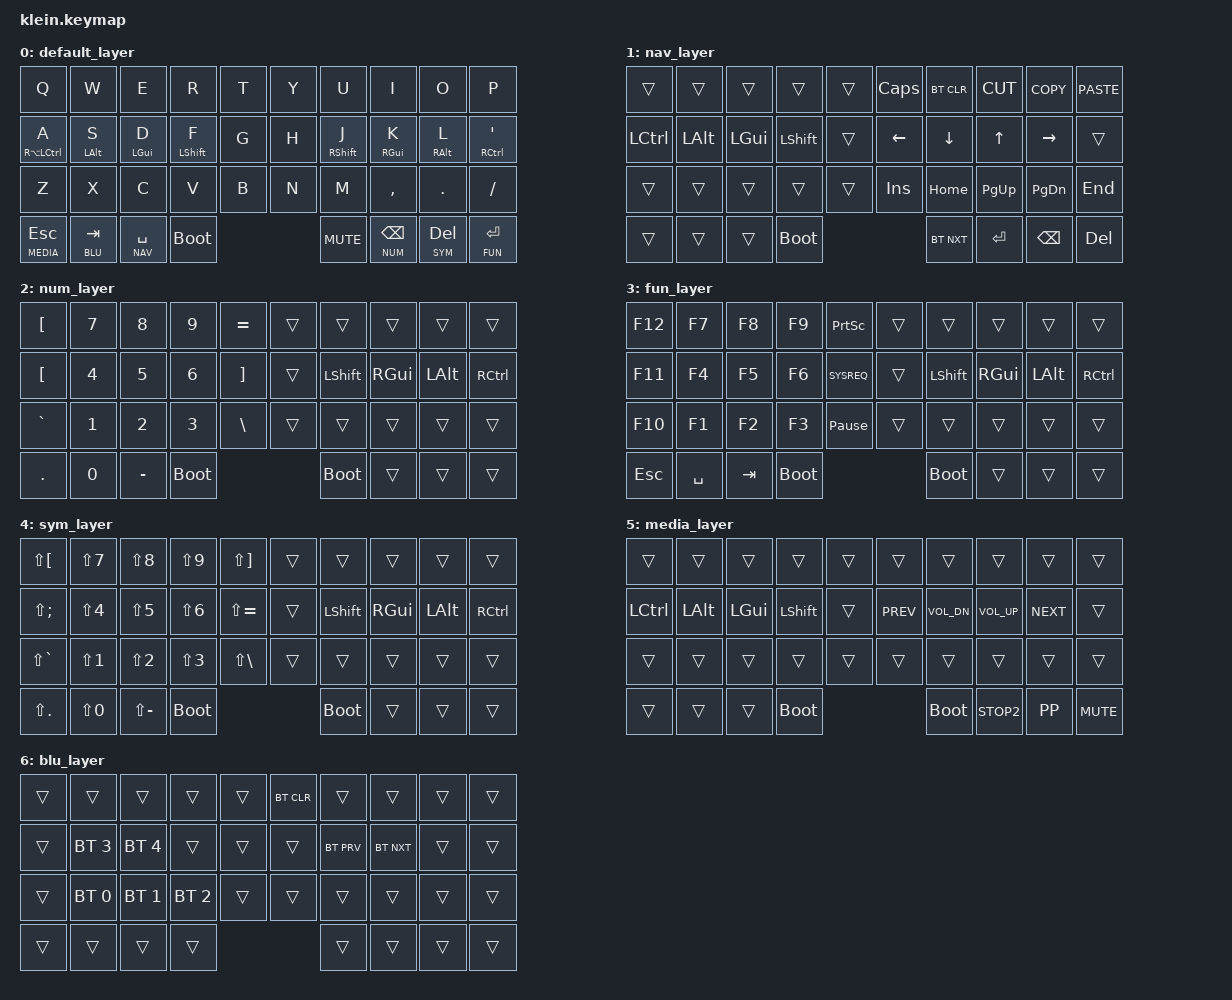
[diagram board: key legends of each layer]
/*
 * Copyright (c) 2020 The ZMK Contributors
 *
 * SPDX-License-Identifier: MIT
 */

#include <behaviors.dtsi>
#include <dt-bindings/zmk/bt.h>
#include <dt-bindings/zmk/keys.h>

#define BASE 0
#define NAV  1
#define NUM  2
#define FUN  3
#define SYM  4
#define MEDIA  5
#define BLU 6

&mt {
    quick-tap-ms = <100>;
    global-quick-tap;
    flavor = "tap-preferred";
    tapping-term-ms = <180>;
};

/ {
    combos {
        compatible = "zmk,combos";

        copy {
            bindings = <&kp LG(C)>;
            key-positions = <21 22>;
            layers = <0>;
        };

        paste {
            bindings = <&kp LG(V)>;
            key-positions = <22 23>;
            layers = <0>;
        };

        leftParet {
            bindings = <&kp LEFT_PARENTHESIS>;
            key-positions = <6 7>;
        };

        rightParet {
            bindings = <&kp RIGHT_PARENTHESIS>;
            key-positions = <7 8>;
            layers = <0>;
        };
    };

    keymap {
        compatible = "zmk,keymap";

        default_layer {
            //          ------------------------------------------------------------------------------------------------------------
            //          |  Q  |  W  |  E   |  R   |  T   |                                           |  Y   |  U    |  I    |  O   |   P   |
            //          |  A  |  S  |  D   |  F   |  G   |                                           |  H   |  J    |  K    |  L   |   '   |
            //          |  Z  |  X  |  C   |  V   |  B   |                                           |  N   |  M    |  ,    |  .   |   /   |
            //                      | ESC  | SPC |  TAB | BOOTLOADER |                         | MUTE | RET | BKSP | DEL |

            bindings = <
&kp Q                 &kp W        &kp E          &kp R        &kp T    &kp Y  &kp U        &kp I         &kp O        &kp P
&mt RA(LEFT_CONTROL) A&mt LALT S   &mt LGUI D     &mt LSHFT F  &kp G    &kp H  &mt RSHFT J  &mt RGUI K    &mt RALT L   &mt RIGHT_CONTROL SQT
&kp Z                 &kp X        &kp C          &kp V        &kp B    &kp N  &kp M        &kp COMMA     &kp DOT      &kp FSLH
&lt MEDIA ESC         &lt BLU TAB  &lt NAV SPACE  &bootloader                  &kp K_MUTE   &lt NUM BSPC  &lt SYM DEL  &lt FUN RET
            >;

            sensor-bindings = <&inc_dec_kp PG_UP PG_DN &inc_dec_kp C_VOL_DN C_VOL_UP>;
        };

        nav_layer {
            bindings = <
&trans          &trans    &trans        &trans       &trans    &kp CAPSLOCK  &bt BT_CLR  &kp K_CUT  &kp K_COPY  &kp K_PASTE
&kp LEFT_CONTROL&kp LALT  &kp LEFT_GUI  &kp LSHFT    &trans    &kp LEFT      &kp DOWN    &kp UP     &kp RIGHT   &trans
&trans          &trans    &trans        &trans       &trans    &kp INSERT    &kp HOME    &kp PG_UP  &kp PG_DN   &kp END
&trans          &trans    &trans        &bootloader                          &bt BT_NXT  &kp RET    &kp BKSP    &kp DEL
            >;

            sensor-bindings = <&inc_dec_kp C_VOL_DN C_VOL_UP>;
        };

        num_layer {
            bindings = <
&kp LBKT        &kp N7  &kp N8     &kp N9       &kp EQUAL            &trans  &trans       &trans         &trans    &trans
&kp LEFT_BRACKET&kp N4  &kp N5     &kp N6       &kp RIGHT_BRACKET    &trans  &kp LSHFT    &kp RIGHT_GUI  &kp LALT  &kp RIGHT_CONTROL
&kp GRAVE       &kp N1  &kp N2     &kp N3       &kp BSLH             &trans  &trans       &trans         &trans    &trans
&kp PERIOD      &kp N0  &kp MINUS  &bootloader                               &bootloader  &trans         &trans    &trans
            >;

            sensor-bindings = <&inc_dec_kp C_VOL_DN C_VOL_UP>;
        };

        fun_layer {
            bindings = <
&kp F12&kp F7     &kp F8   &kp F9       &kp PSCRN          &trans  &trans       &trans         &trans    &trans
&kp F11&kp F4     &kp F5   &kp F6       &kp SYSREQ         &trans  &kp LSHFT    &kp RIGHT_GUI  &kp LALT  &kp RIGHT_CONTROL
&kp F10&kp F1     &kp F2   &kp F3       &kp PAUSE_BREAK    &trans  &trans       &trans         &trans    &trans
&kp ESC&kp SPACE  &kp TAB  &bootloader                             &bootloader  &trans         &trans    &trans
            >;

            sensor-bindings = <&inc_dec_kp C_VOL_DN C_VOL_UP>;
        };

        sym_layer {
            bindings = <
&kp LS(LBKT)  &kp LS(N7)  &kp LS(N8)     &kp LS(N9)   &kp LS(RBKT)     &trans  &trans       &trans    &trans    &trans
&kp LS(SEMI)  &kp LS(N4)  &kp LS(N5)     &kp LS(N6)   &kp LS(EQUAL)    &trans  &kp LSHFT    &kp RGUI  &kp LALT  &kp RIGHT_CONTROL
&kp LS(GRAVE) &kp LS(N1)  &kp LS(N2)     &kp LS(N3)   &kp LS(BSLH)     &trans  &trans       &trans    &trans    &trans
&kp LS(PERIOD)&kp LS(N0)  &kp LS(MINUS)  &bootloader                           &bootloader  &trans    &trans    &trans
            >;

            sensor-bindings = <&inc_dec_kp C_VOL_DN C_VOL_UP>;
        };

        media_layer {
            bindings = <
&trans          &trans    &trans        &trans       &trans    &trans      &trans        &trans        &trans      &trans
&kp LEFT_CONTROL&kp LALT  &kp LEFT_GUI  &kp LSHFT    &trans    &kp K_PREV  &kp K_VOL_DN  &kp K_VOL_UP  &kp K_NEXT  &trans
&trans          &trans    &trans        &trans       &trans    &trans      &trans        &trans        &trans      &trans
&trans          &trans    &trans        &bootloader                        &bootloader   &kp K_STOP2   &kp K_PP    &kp K_MUTE
            >;

            sensor-bindings = <&inc_dec_kp C_VOL_DN C_VOL_UP>;
        };

        blu_layer {
            bindings = <
&trans&trans        &trans        &trans        &trans    &bt BT_CLR  &trans      &trans      &trans  &trans
&trans&bt BT_SEL 3  &bt BT_SEL 4  &trans        &trans    &trans      &bt BT_PRV  &bt BT_NXT  &trans  &trans
&trans&bt BT_SEL 0  &bt BT_SEL 1  &bt BT_SEL 2  &trans    &trans      &trans      &trans      &trans  &trans
&trans&trans        &trans        &trans                              &trans      &trans      &trans  &trans
            >;

            sensor-bindings = <&inc_dec_kp C_VOL_DN C_VOL_UP>;
        };
    };
};
